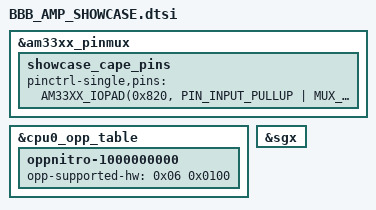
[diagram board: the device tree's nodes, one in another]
/*
 * Copyright (C) 2012 Texas Instruments Incorporated - http://www.ti.com/
 *
 * This program is free software; you can redistribute it and/or modify
 * it under the terms of the GNU General Public License version 2 as
 * published by the Free Software Foundation.
 */
&am33xx_pinmux {
        showcase_cape_pins: showcase_cape_pins {
                pinctrl-single,pins = <
                        AM33XX_IOPAD(0x820, PIN_INPUT_PULLUP | MUX_MODE7)    /* 0x020 0x37  LB5 (Input)                BB-P8.19          U10, GPMC_AD8       gpio0_22(7)                  0x820=0x27 PD, I */
                        AM33XX_IOPAD(0x824, PIN_OUTPUT_PULLDOWN | MUX_MODE7) /* 0x024 0x07  Compressor (Output)        BB-P8.13          T10, GPMC_AD9       gpio0_23(7)                  0x824=0x27 PD, I */
                        AM33XX_IOPAD(0x828, PIN_INPUT_PULLUP | MUX_MODE7)    /* 0x028 0x37  LB3 (Input)                BB-P8.14          T11, GPMC_AD10      gpio0_26(7)                  0x828=0x27 PD, I */
                        AM33XX_IOPAD(0x82c, PIN_INPUT_PULLUP | MUX_MODE7)    /* 0x02c 0x37  LB4 (Input)                BB-P8.17          U12, GPMC_AD11      gpio0_27(7)                  0x82c=0x27 PD, I */
                        AM33XX_IOPAD(0x830, PIN_OUTPUT_PULLDOWN | MUX_MODE7) /* 0x030 0x07  Valve 1 (Output)           BB-P8.12  FT-P18  T12  GPMC_AD12      pru0_gpo(6),gpio1_12(7)      0x830=0x6  PD, O */
                        AM33XX_IOPAD(0x834, PIN_OUTPUT_PULLDOWN | MUX_MODE7) /* 0x034 0x07  Motor (Output)             BB-P8.11  FT-P17  R12  GPMC_AD13      pru0_gpo(6),gpio1_13(7)      0x834=0x27 PD, I */
                        AM33XX_IOPAD(0x838, PIN_INPUT_PULLUP | MUX_MODE7)    /* 0x038 0x37  LightBarrier 1 (Input)     BB-P8.16  FT-P6   V13  GPMC_AD14      pru0_gpi(6),gpio1_14(7)      0x838=0x27 PD, I */
                        AM33XX_IOPAD(0x83c, PIN_INPUT_PULLUP | MUX_MODE7)    /* 0x03c 0x37  Pulse Counter (Input)      BB-P8.15  FT-P5   U13  GPMC_AD15      pru0_gpi(6),gpio1_15(7)      0x83c=0x27 PD, I */
                        AM33XX_IOPAD(0x86c, PIN_OUTPUT_PULLDOWN | MUX_MODE7) /* 0x06c 0x07  (Output=0 to disable Clk)                    V17  GPMC_A11       gpio1_27(7)                  0x86c=0x27 PD, I */
                        AM33XX_IOPAD(0x984, PIN_INPUT_PULLUP | MUX_MODE7)    /* 0x184 0x37  LightBarrier 2 (Input)     BB-P9.24  FT-P7   D15  UART1_TXD      pru0_gpi(6),gpio0_15(7)      0x984=0x37 PU, I */
                        AM33XX_IOPAD(0x998, PIN_INPUT_PULLUP | MUX_MODE7)    /* 0x198 0x37  LB3 && LB4 && LB5 (Input)  BB-P9.30  FT-P21  D12  MCASP0_AXR0    pru0_gpio2(5,6),gpio3_16(7)  0x998=0x27 PD, I */
                        AM33XX_IOPAD(0x9a4, PIN_OUTPUT_PULLDOWN | MUX_MODE7) /* 0x1a4 0x07  Valve 3 (Output)           BB-P9.27  FT-P11  C13  MCASP0_FSR     pru0_gpio5(5,6),gpio3_19(7)  0x9a4=0x27 PD, I */
                        AM33XX_IOPAD(0x9ac, PIN_OUTPUT_PULLDOWN | MUX_MODE7) /* 0x1ac 0x07  Valve 2 (Output)           BB-P9.25  FT-P10  A14  MCASP0_AHCLKX  pru0_gpio7(5,6),gpio3_21(7)  0x9ac=0x27 PD, I */
			AM33XX_IOPAD(0x9b4, PIN_OUTPUT_PULLDOWN | MUX_MODE3) /* clkout2_pin-definition from am335x-bone-common.dtsi (not referenced any more) */
                >;
        };
};


&cpu0_opp_table {
	/*
	 * All PG 2.0 silicon may not support 1GHz but some of the early
	 * BeagleBone Blacks have PG 2.0 silicon which is guaranteed
	 * to support 1GHz OPP so enable it for PG 2.0 on this board.
	 */
	oppnitro-1000000000 {
		opp-supported-hw = <0x06 0x0100>;
	};
};

&sgx {
    status = "okay";
};
